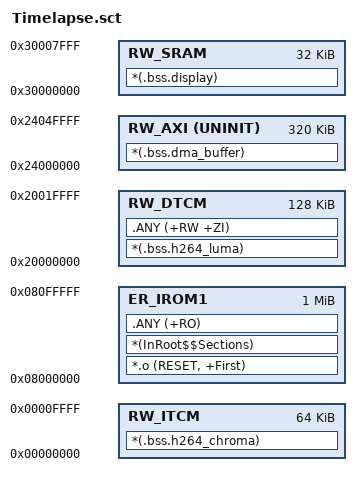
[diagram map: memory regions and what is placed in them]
; STM32H723VG: Flash — код, AXI — камера/кодек, DTCM/ITCM — YUV, D2 — экран.
LR_IROM1 0x08000000 0x00100000
{
  ER_IROM1 0x08000000 0x00100000
  {
    *.o (RESET, +First)
    *(InRoot$$Sections)
    .ANY (+RO)
  }
  RW_AXI 0x24000000 UNINIT 0x00050000
  {
    *(.bss.dma_buffer)
  }
  RW_DTCM 0x20000000 0x00020000
  {
    *(.bss.h264_luma)
    .ANY (+RW +ZI)
  }
  RW_ITCM 0x00000000 0x00010000
  {
    *(.bss.h264_chroma)
  }
  RW_SRAM 0x30000000 0x00008000
  {
    *(.bss.display)
  }
}
